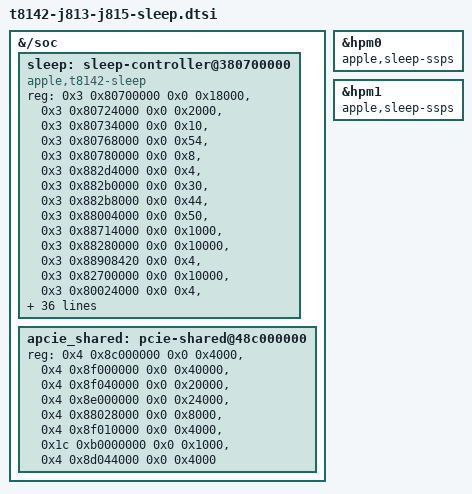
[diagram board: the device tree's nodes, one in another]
// SPDX-License-Identifier: GPL-2.0+ OR MIT
/*
 * Suspend-to-RAM on the 13- and 15-inch M5 MacBook Air (J813, J815): the sleep controller,
 * the shared PCIe block the wake brings back, and the port controllers' sleep power state.
 * Included at the end of each board's device tree, after the nodes it refers to.
 *
 * The boot core's power gate (cluster_pwrgate), the internal display's power words (dcp_power)
 * and the DCP DART's PS write-disable bit are in t8142-j813-j815.dtsi (aurora-silicon/linux#1942,
 * #1941).
 */

#include <dt-bindings/gpio/gpio.h>

/*
 * Suspend-to-RAM (apple,t8142-sleep): derived from macOS 27.2.1 and T8132's measurements, and
 * dry-run gated in the driver (apple_sleep.deep, apple_sleep.untested_commit). The J813 and J815
 * ADTs (27.0) differ only in audio, product and CLPC power-limit properties: every block, wake
 * source, GPIO and PCIe window below is the same on both.
 */
&{/soc} {
	/*
	 * Suspend-to-RAM. The blocks are T8132's, at the same J815 ADT indices: /arm-io/pmgr
	 * reg[32] (ps), [34] (pwrgate), [42] (cpu-start), [45] (cllt; EARLY_WAKEUP_CFG at
	 * +0x50), [36] (cluster), [40] + 0x4000 (commit), [38] (aon-misc), [4] (wake: nine mask
	 * and nine status words), [1] (ps-aon), /arm-io/wdt, nub-spmi0, nub-spmi-a0, the
	 * PMC's voter floors (as &pmc), and the SoC and DCS perf-state words that
	 * AppleT8142PMGR::setPerfState writes (reg[2] + 0x24000, + 0x25000).
	 * Derived from macOS 27.2.1 and T8132's measurements, never run on an M5: the driver
	 * stops each sleep at a dry run unless booted with apple_sleep.untested_commit=1,
	 * and deep sleep is only used when asked for (mem_sleep).
	 */
	sleep: sleep-controller@380700000 {
		compatible = "apple,t8142-sleep";
		reg = <0x3 0x80700000 0x0 0x18000>,
		      <0x3 0x80724000 0x0 0x2000>,
		      <0x3 0x80734000 0x0 0x10>,
		      <0x3 0x80768000 0x0 0x54>,
		      <0x3 0x80780000 0x0 0x8>,
		      <0x3 0x882d4000 0x0 0x4>,
		      <0x3 0x882b0000 0x0 0x30>,
		      <0x3 0x882b8000 0x0 0x44>,
		      <0x3 0x88004000 0x0 0x50>,
		      /* SPMI gen 4: queue at +0x200..0x220, notify enable/ack +0x420/+0x620 */
		      <0x3 0x88714000 0x0 0x1000>,
		      <0x3 0x88280000 0x0 0x10000>,
		      /* nub-spmi-a0's notify enable word (gen 4: +0x420; gen 1 had +0x40) */
		      <0x3 0x88908420 0x0 0x4>,
		      <0x3 0x82700000 0x0 0x10000>,
		      <0x3 0x80024000 0x0 0x4>,
		      <0x3 0x80025000 0x0 0x4>,
		      /*
		       * Each complex's ACC word 0x40f8 (ADT pmgr reg[7] E, reg[18] P, + 0x40f8),
		       * which AppleT8142PMGR sets to 1 after the complex powers on and at the
		       * end of restoreHW.
		       */
		      <0x2 0x10e440f8 0x0 0x4>,
		      <0x2 0x11e440f8 0x0 0x4>,
		      /*
		       * The memory side macOS steps down last (J813 trace, same ADT mcc layout
		       * on J815): each AMCC plane's +0x28000 word (mcc reg[1], planes 0x40000
		       * apart), the six SoC NI tables (reg[2..7]), the eight DCS channels'
		       * words from +0x580 (reg[10..17]) and the clock word 0x380038000.
		       */
		      <0x2 0x20028000 0x0 0x8>,
		      <0x2 0x20068000 0x0 0x8>,
		      <0x2 0x200a8000 0x0 0x8>,
		      <0x2 0x200e8000 0x0 0x8>,
		      <0x2 0x4f010000 0x0 0x104>,
		      <0x2 0x50010000 0x0 0x104>,
		      <0x2 0x51010000 0x0 0x104>,
		      <0x2 0x52010000 0x0 0x104>,
		      <0x2 0x53010000 0x0 0x104>,
		      <0x2 0x54010000 0x0 0x104>,
		      <0x2 0x21000580 0x0 0x104>,
		      <0x2 0x21200580 0x0 0x104>,
		      <0x2 0x21400580 0x0 0x104>,
		      <0x2 0x21600580 0x0 0x104>,
		      <0x2 0x21800580 0x0 0x104>,
		      <0x2 0x21a00580 0x0 0x104>,
		      <0x2 0x21c00580 0x0 0x104>,
		      <0x2 0x21e00580 0x0 0x104>,
		      <0x3 0x80038000 0x0 0x4>,
		      /*
		       * What the deep sleep loses and XNU restores at the wake (J813 ten-core
		       * trace, 2026-11-16): the PMGR clkgen's 126 slots (0x20 apart from
		       * 0x380038100) and each AMCC plane's control words (+0x2a000..+0x2e003).
		       * The SoC NI tables above reach their strobe word at +0x100.
		       */
		      <0x3 0x80038100 0x0 0xfc0>,
		      <0x2 0x2002a000 0x0 0x4004>,
		      <0x2 0x2006a000 0x0 0x4004>,
		      <0x2 0x200aa000 0x0 0x4004>,
		      <0x2 0x200ea000 0x0 0x4004>;
		reg-names = "ps", "pwrgate", "cpu-start", "cllt", "cluster",
			    "commit", "wdt", "aon-misc", "wake", "spmi",
			    "ps-aon", "spmi-a0", "pmc-voters", "clk-perf", "dcs",
			    "acc-e", "acc-p",
			    "amcc0", "amcc1", "amcc2", "amcc3",
			    "socni0", "socni1", "socni2", "socni3", "socni4", "socni5",
			    "mcc0", "mcc1", "mcc2", "mcc3", "mcc4", "mcc5", "mcc6", "mcc7",
			    "mem-clk", "clk-slots",
			    "amcc-cfg0", "amcc-cfg1", "amcc-cfg2", "amcc-cfg3";
		/*
		 * From the J815 ADT's /arm-io/pmgr ap-wake-sources, the same sources
		 * as T8132's by name: NUB.SPMI0.SW3, ATC0.USBWakeup, SMC.CPUWakeupAP,
		 * SMC.OutboxNotEmpty, MTP.DOCK.CHANNELS.AP0.IRQ and MTP.OutboxNotEmpty.
		 */
		apple,wake-enable = <152 72 168 190 89 108>;
		/* PMU RTC: peripheral source 2, routed through NUB.SPMI0.SW3 (wake source 152). */
		apple,spmi-pmu-sources = <0x600 0x4>;
		/*
		 * The DCP, then the external DCPs once the tree describes them (dcpext0, dcpext1):
		 * the sleep lowers them with the display, and refuses while an undescribed one is up.
		 */
		apple,display-coprocessors = <&dcp>;
		/* ANS's link's shared block, and the radio's link, which only aura trains */
		apple,apcie = <&apcie_shared>;
		apple,radio-host = <&pcie0>;
		/* ADT pci-bridge0 function-perst: AP GPIO 192 */
		apple,radio-perst = <&pinctrl_ap 192 GPIO_ACTIVE_LOW>;
		apple,pinctrl = <&pinctrl_ap>;
		/* The ADT's no-restore-gpio-pins: reading pin 78 raises an SError. */
		apple,pinctrl-skip-pins = <78 203>;
	};

	/*
	 * ANS's side of the shared PCIe block, which the sleep controller brings back after a
	 * real sleep in AppleT8142PCIe's order (as aura's j813_n1.c at boot): ADT /arm-io/apcie
	 * reg[1] (rc), [2] (phy-block; its PHY-PHY control words are reg[3], 0x20000 in), [4]
	 * (phy-ip) and [5] (axi2af, as far as its tables reach). Then the radio's port 0, which
	 * it trains again after the wake: reg[8] (radio-port), [10] (radio-lane) and the root
	 * port's configuration space (radio-cfg, the ECAM's first 4 KiB). reg[6] (clkgen, the
	 * pcieclkgen whose PLLs APCIECoreRCGen4 shuts down before the power goes; AppleT8142PCIe
	 * maps reg[7] as its AUS5 AON top, unused here). aura copies the ADT's
	 * apcie-{axi2af,phy,phy-ip-pll,phy-ip-auspma}-tunables and pci-bridge0's
	 * apcie-config-tunables and pcie-rc{,-gen3-shadow,-gen4-shadow}-tunables here. No
	 * driver binds it.
	 */
	apcie_shared: pcie-shared@48c000000 {
		reg = <0x4 0x8c000000 0x0 0x4000>,
		      <0x4 0x8f000000 0x0 0x40000>,
		      <0x4 0x8f040000 0x0 0x20000>,
		      <0x4 0x8e000000 0x0 0x24000>,
		      <0x4 0x88028000 0x0 0x8000>,
		      <0x4 0x8f010000 0x0 0x4000>,
		      <0x1c 0xb0000000 0x0 0x1000>,
		      <0x4 0x8d044000 0x0 0x4000>;
		reg-names = "rc", "phy-block", "phy-ip", "axi2af",
			    "radio-port", "radio-lane", "radio-cfg", "clkgen";
	};
};

/*
 * The port controllers' system power state (SSPS 3 before the commit, 0 at the wake), as
 * macOS's AppleHPM sends it on the J700 and J714s, measured there on the same SN201202x;
 * not traced on an M5 Air. Only a firmware-driven sleep sends it, and a controller that
 * does not take S3 refuses the sleep (tipd's cd321x_prepare()).
 */
&hpm0 {
	apple,sleep-ssps;
};

&hpm1 {
	apple,sleep-ssps;
};
